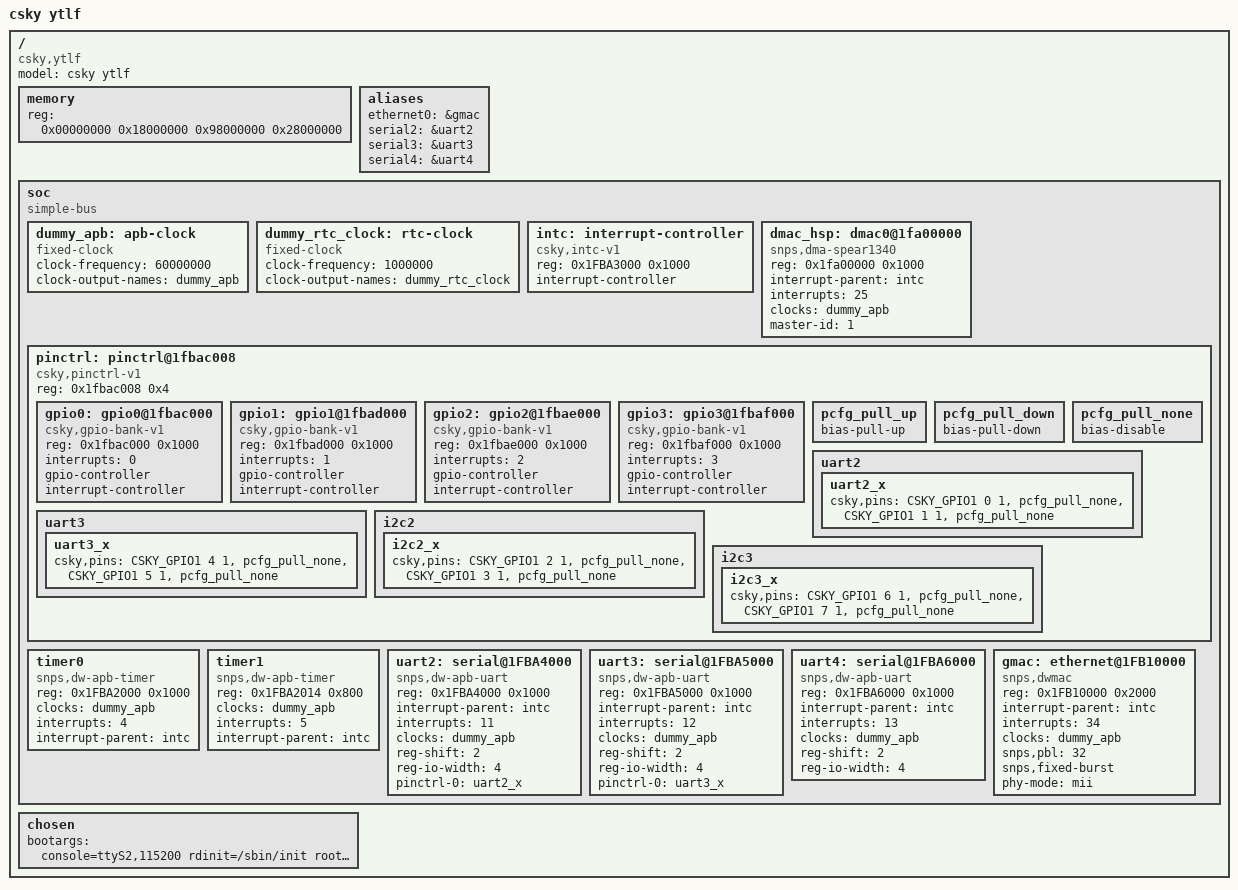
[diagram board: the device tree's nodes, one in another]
/dts-v1/;
#include <dt-bindings/interrupt-controller/irq.h>
#include <dt-bindings/gpio/gpio.h>
#include <dt-bindings/input/input.h>
#include "../../../../addons/drivers/pinctrl/pinctrl-csky.h"

/* Use macro TEST_PINMUX to test PINMUX.
 * From user manual, GPIO1-4/GPIO1-5 is pinmux with UART3's TX and RX.
 * When TEST_PINMUX is not defined, these 2 pins work as UART3.
 * When TEST_PINMUX is defined, these 2 pins work as GPIO act as LEDs.
 */
//#define TEST_PINMUX

/ {
	model = "csky ytlf";
	compatible = "csky,ytlf";
	#address-cells = <1>;
	#size-cells = <1>;

	memory {
		device_type = "memory";
		reg = <0x00000000 0x18000000 0x98000000 0x28000000>;
	};

	aliases {
		ethernet0 = &gmac;
		serial2 = &uart2;
#ifndef TEST_PINMUX
		serial3 = &uart3;
#endif
		serial4 = &uart4;
	};

	soc {
		#address-cells = <1>;
		#size-cells = <1>;
		compatible = "simple-bus";
		ranges;

		dummy_apb: apb-clock {
			compatible = "fixed-clock";
			clock-frequency = <60000000>;
			clock-output-names = "dummy_apb";
			#clock-cells = <0>;
		};
		dummy_rtc_clock: rtc-clock {
			compatible = "fixed-clock";
			clock-frequency = <1000000>;
			clock-output-names = "dummy_rtc_clock";
			#clock-cells = <0>;
		};

		intc: interrupt-controller {
			compatible = "csky,intc-v1";
			reg = <0x1FBA3000 0x1000>;
			interrupt-controller;
			#interrupt-cells = <1>;
		};

		dmac_hsp: dmac0@1fa00000 {
			compatible = "snps,dma-spear1340";
			reg = <0x1fa00000 0x1000>;
			interrupt-parent = <&intc>;
			interrupts = <25>;
			clocks = <&dummy_apb>;
			clock-names = "hclk";
			#dma-cells = <3>;
			master-id = <1>;
		};

		pinctrl: pinctrl@1fbac008 {
			compatible = "csky,pinctrl-v1";
			reg = <0x1fbac008 0x4>;

			#address-cells = <1>;
			#size-cells = <1>;
			ranges;

			gpio0: gpio0@1fbac000 {
				compatible = "csky,gpio-bank-v1";
				reg = <0x1fbac000 0x1000>;
				interrupts = <0>;

				gpio-controller;
				#gpio-cells = <2>;

				interrupt-controller;
				#interrupt-cells = <2>;
			};

			gpio1: gpio1@1fbad000 {
				compatible = "csky,gpio-bank-v1";
				reg = <0x1fbad000 0x1000>;
				interrupts = <1>;

				gpio-controller;
				#gpio-cells = <2>;

				interrupt-controller;
				#interrupt-cells = <2>;
			};

			gpio2: gpio2@1fbae000 {
				compatible = "csky,gpio-bank-v1";
				reg = <0x1fbae000 0x1000>;
				interrupts = <2>;

				gpio-controller;
				#gpio-cells = <2>;

				interrupt-controller;
				#interrupt-cells = <2>;
			};

			gpio3: gpio3@1fbaf000 {
				compatible = "csky,gpio-bank-v1";
				reg = <0x1fbaf000 0x1000>;
				interrupts = <3>;

				gpio-controller;
				#gpio-cells = <2>;

				interrupt-controller;
				#interrupt-cells = <2>;
			};

			pcfg_pull_up: pcfg_pull_up {
				bias-pull-up;
			};

			pcfg_pull_down: pcfg_pull_down {
				bias-pull-down;
			};

			pcfg_pull_none: pcfg_pull_none {
				bias-disable;
			};

			uart2 {
				uart2_x: uart2_x {
					csky,pins = <CSKY_GPIO1 0 1 &pcfg_pull_none>,
						    <CSKY_GPIO1 1 1 &pcfg_pull_none>;
				};
			};

			uart3 {
				uart3_x: uart3_x {
					csky,pins = <CSKY_GPIO1 4 1 &pcfg_pull_none>,
						    <CSKY_GPIO1 5 1 &pcfg_pull_none>;
				};
			};

			i2c2 {
				i2c2_x: i2c2_x {
					csky,pins = <CSKY_GPIO1 2 1 &pcfg_pull_none>,
						    <CSKY_GPIO1 3 1 &pcfg_pull_none>;
				};
			};

			i2c3 {
				i2c3_x: i2c3_x {
					csky,pins = <CSKY_GPIO1 6 1 &pcfg_pull_none>,
						    <CSKY_GPIO1 7 1 &pcfg_pull_none>;
				};
			};
		};

		/* clockevent */
		timer0 {
			compatible = "snps,dw-apb-timer";
			reg = <0x1FBA2000 0x1000>;
			clocks = <&dummy_apb>;
			clock-names = "timer";
			interrupts = <4>;
			interrupt-parent = <&intc>;
		};

		/* clocksource */
		timer1 {
			compatible = "snps,dw-apb-timer";
			reg = <0x1FBA2014 0x800>;
			clocks = <&dummy_apb>;
			clock-names = "timer";
			interrupts = <5>;
			interrupt-parent = <&intc>;
		};

		uart2: serial@1FBA4000 {
			compatible = "snps,dw-apb-uart";
			reg = <0x1FBA4000 0x1000>;
			interrupt-parent = <&intc>;
			interrupts = <11>;
			clocks = <&dummy_apb>;
			clock-names = "baudclk";
			reg-shift = <2>;
			reg-io-width = <4>;
			pinctrl-names = "default";
			pinctrl-0 = <&uart2_x>;
		};
#ifndef TEST_PINMUX
		uart3: serial@1FBA5000 {
			compatible = "snps,dw-apb-uart";
			reg = <0x1FBA5000 0x1000>;
			interrupt-parent = <&intc>;
			interrupts = <12>;
			clocks = <&dummy_apb>;
			clock-names = "baudclk";
			reg-shift = <2>;
			reg-io-width = <4>;
			pinctrl-names = "default";
			pinctrl-0 = <&uart3_x>;
		};
#endif
		uart4: serial@1FBA6000 {
			compatible = "snps,dw-apb-uart";
			reg = <0x1FBA6000 0x1000>;
			interrupt-parent = <&intc>;
			interrupts = <13>;
			clocks = <&dummy_apb>;
			clock-names = "baudclk";
			reg-shift = <2>;
			reg-io-width = <4>;
		};

		gmac: ethernet@1FB10000 {
			compatible = "snps,dwmac";
			reg = <0x1FB10000 0x2000>;
			interrupt-parent = <&intc>;
			interrupts = <34>;
			interrupt-names = "macirq";
			clocks = <&dummy_apb>;
			clock-names = "stmmaceth";
			snps,pbl = <32>;
			snps,fixed-burst;
#if 1
			phy-mode = "mii";
#else
			phy-mode = "rgmii";
			phy-handle = <&phy_88E1512>;

			mdio0 {
				#address-cells = <1>;
				#size-cells = <0>;
				compatible = "snps,dwmac-mdio";

				phy_88E1512: ethernet-phy@0 {
					reg = <0>;
					marvell,reg-init = /* <page reg mask value> */
						<3 16 0xF000 0x630>, /* LED[0]-link, LED[1]-activity, LED[2]-speed */
						<3 17 0xFF00 0x15>; /* LED Polarity: On-High, Off-Low */
				};
			};
#endif
		};
	};

	chosen {
		// bootargs = "console=ttyS2,115200 init=/sbin/init root=/dev/nfs rw nfsroot=172.16.28.184:/home/rtos_nfs/br/rootfs,v3,tcp,nolock ip=172.16.150.100::172.16.150.254:255.255.255.0";
		bootargs = "console=ttyS2,115200 rdinit=/sbin/init root=/dev/ram0 cma=128M";
	};
};

